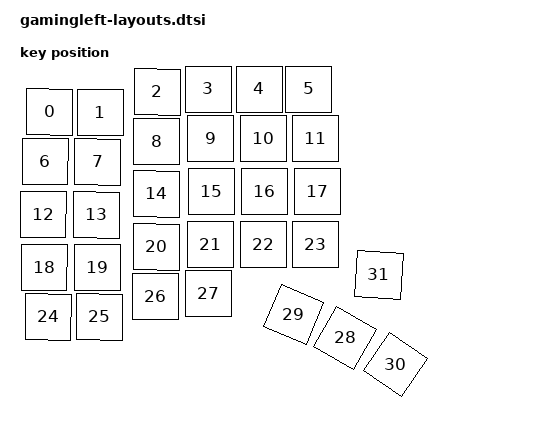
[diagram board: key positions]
#include <physical_layouts.dtsi>

/ {
    default_layout: physical_layout_0 {
        compatible = "zmk,physical-layout";
        display-name = "Default Layout";
        transform = <&default_transform>;

        keys
            = <&key_physical_attrs 100 100 13 46 41 63 96>
            , <&key_physical_attrs 100 100 114 47 40 164 97>
            , <&key_physical_attrs 100 100 228 6 40 278 56>
            , <&key_physical_attrs 100 100 330 0 0 0 0>
            , <&key_physical_attrs 100 100 432 0 0 0 0>
            , <&key_physical_attrs 100 100 531 0 0 0 0>
            , <&key_physical_attrs 100 100 4 145 41 54 195>
            , <&key_physical_attrs 100 100 109 146 40 159 196>
            , <&key_physical_attrs 100 100 227 105 40 277 155>
            , <&key_physical_attrs 100 100 335 99 0 0 0>
            , <&key_physical_attrs 100 100 440 99 0 0 0>
            , <&key_physical_attrs 100 100 544 99 0 0 0>
            , <&key_physical_attrs 100 100 0 251 41 50 301>
            , <&key_physical_attrs 100 100 107 252 40 157 302>
            , <&key_physical_attrs 100 100 227 210 40 277 260>
            , <&key_physical_attrs 100 100 336 205 0 0 0>
            , <&key_physical_attrs 100 100 443 205 0 0 0>
            , <&key_physical_attrs 100 100 548 205 0 0 0>
            , <&key_physical_attrs 100 100 2 357 41 52 407>
            , <&key_physical_attrs 100 100 108 357 40 158 407>
            , <&key_physical_attrs 100 100 226 316 40 276 366>
            , <&key_physical_attrs 100 100 335 311 0 0 0>
            , <&key_physical_attrs 100 100 440 311 0 0 0>
            , <&key_physical_attrs 100 100 544 311 0 0 0>
            , <&key_physical_attrs 100 100 10 456 41 60 506>
            , <&key_physical_attrs 100 100 112 456 40 162 506>
            , <&key_physical_attrs 100 100 225 415 40 275 465>
            , <&key_physical_attrs 100 100 330 409 0 0 0>
            , <&key_physical_attrs 100 100 604 498 12042 654 548>
            , <&key_physical_attrs 100 100 501 451 11262 551 501>
            , <&key_physical_attrs 100 100 705 551 12442 755 601>
            , <&key_physical_attrs 100 100 671 372 (-8655) 721 422>
            ;
    };
};
